AUTOSAR XML (schema 314)
package /ComponentType
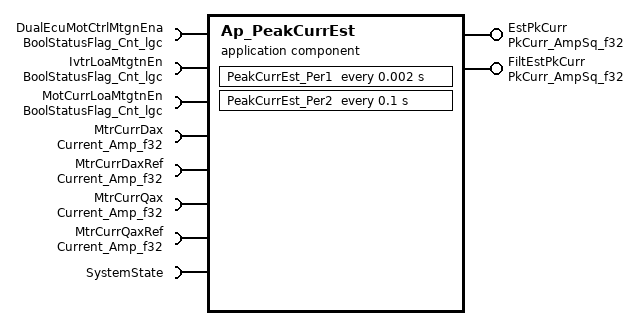
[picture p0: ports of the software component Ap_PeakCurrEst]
  application software component type Ap_PeakCurrEst
    provide port EstPkCurr: unqueued-sender-com-spec{data-element=AmpSq_f32, can-invalidate=false, init-value=D_ZERO_ULS_F32}, provided-interface=PkCurr_AmpSq_f32
    provide port FiltEstPkCurr: unqueued-sender-com-spec{data-element=AmpSq_f32, can-invalidate=false, init-value=D_ZERO_ULS_F32}, provided-interface=PkCurr_AmpSq_f32
    8 x require port:
      DualEcuMotCtrlMtgnEna: unqueued-receiver-com-spec{data-element=Cnt_lgc, init-value=D_FALSE_CNT_LGC}, required-interface=BoolStatusFlag_Cnt_lgc
      IvtrLoaMtgtnEn: unqueued-receiver-com-spec{data-element=Cnt_lgc, init-value=D_FALSE_CNT_LGC}, required-interface=BoolStatusFlag_Cnt_lgc
      MotCurrLoaMtgtnEn: unqueued-receiver-com-spec{data-element=Cnt_lgc, init-value=D_FALSE_CNT_LGC}, required-interface=BoolStatusFlag_Cnt_lgc
      MtrCurrDax: unqueued-receiver-com-spec{data-element=Amp_f32, init-value=D_ZERO_ULS_F32}, required-interface=Current_Amp_f32
      MtrCurrDaxRef: unqueued-receiver-com-spec{data-element=Amp_f32, init-value=D_ZERO_ULS_F32}, required-interface=Current_Amp_f32
      MtrCurrQax: unqueued-receiver-com-spec{data-element=Amp_f32, init-value=D_ZERO_ULS_F32}, required-interface=Current_Amp_f32
      MtrCurrQaxRef: unqueued-receiver-com-spec{data-element=Amp_f32, init-value=D_ZERO_ULS_F32}, required-interface=Current_Amp_f32
      SystemState: required-interface=SystemState
  internal behavior Ap_PeakCurrEst_InternalBehavior: component=Ap_PeakCurrEst
    timing event TMT_PeakCurrEst_Per1: mode-dependency=dependent-on-mode=SystemState.Mode.WARMINIT, start-on-event=PeakCurrEst_Per1, period=0.002
    timing event TMT_PeakCurrEst_Per2: mode-dependency=dependent-on-mode=SystemState.Mode.WARMINIT, start-on-event=PeakCurrEst_Per2, period=0.1
    port-api-options:
      enable-take-address=false, indirect-api=false, port=DualEcuMotCtrlMtgnEna
      enable-take-address=false, indirect-api=false, port=EstPkCurr
      enable-take-address=false, indirect-api=false, port=FiltEstPkCurr
      enable-take-address=false, indirect-api=false, port=IvtrLoaMtgtnEn
      enable-take-address=false, indirect-api=false, port=MotCurrLoaMtgtnEn
      enable-take-address=false, indirect-api=false, port=MtrCurrDax
      enable-take-address=false, indirect-api=false, port=MtrCurrDaxRef
      enable-take-address=false, indirect-api=false, port=MtrCurrQax
      enable-take-address=false, indirect-api=false, port=MtrCurrQaxRef
      enable-take-address=false, indirect-api=false, port=SystemState
    runnable PeakCurrEst_Per1
      7 x data read access:
        READ_DualEcuMotCtrlMtgnEna_Cnt_lgc: data-element=DualEcuMotCtrlMtgnEna.Cnt_lgc
        READ_IvtrLoaMtgtnEn_Cnt_lgc: data-element=IvtrLoaMtgtnEn.Cnt_lgc
        READ_MotCurrLoaMtgtnEn_Cnt_lgc: data-element=MotCurrLoaMtgtnEn.Cnt_lgc
        READ_MtrCurrDax_Amp_f32: data-element=MtrCurrDax.Amp_f32
        READ_MtrCurrDaxRef_Amp_f32: data-element=MtrCurrDaxRef.Amp_f32
        READ_MtrCurrQax_Amp_f32: data-element=MtrCurrQax.Amp_f32
        READ_MtrCurrQaxRef_Amp_f32: data-element=MtrCurrQaxRef.Amp_f32
      data write access WRITE_EstPkCurr_AmpSq_f32: data-element=EstPkCurr.AmpSq_f32
    runnable PeakCurrEst_Per2
      data write access WRITE_FiltEstPkCurr_AmpSq_f32: data-element=FiltEstPkCurr.AmpSq_f32
  swc implementation Ap_PeakCurrEst_Implementation: behavior=Ap_PeakCurrEst_InternalBehavior
    code-descriptors:
      code Code: type=SRC
